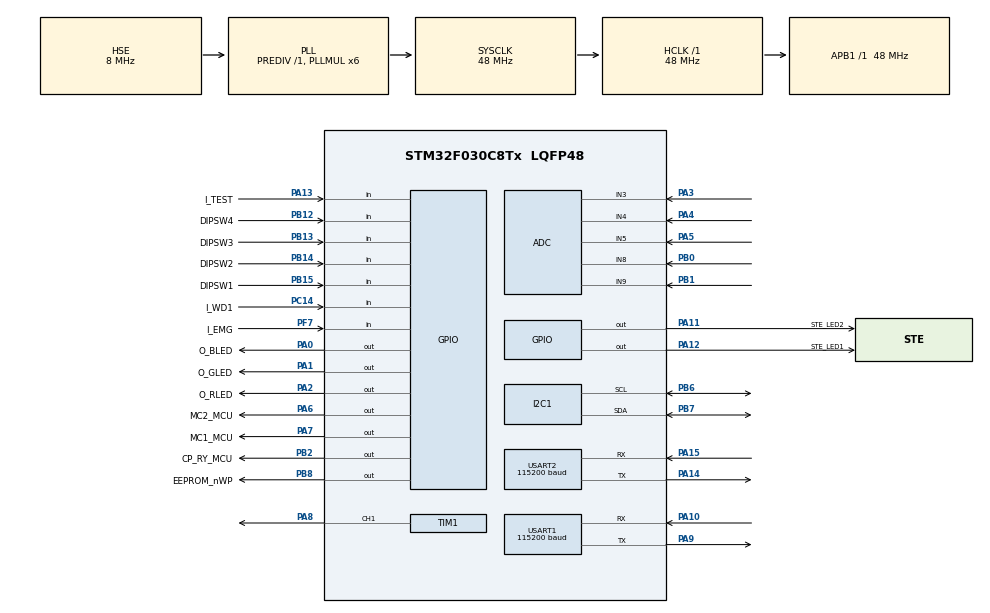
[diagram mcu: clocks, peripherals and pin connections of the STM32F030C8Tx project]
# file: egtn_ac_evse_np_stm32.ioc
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Mcu.Family=STM32F0
Dma.ADC.0.Mode=DMA_CIRCULAR
USART1.BaudRate=115200
PB14.GPIO_Label=DIPSW2
PA0.GPIO_Label=O_BLED
Dma.ADC.0.Priority=DMA_PRIORITY_LOW
PA6.GPIO_Label=MC2_MCU
PB13.GPIO_Label=DIPSW3
PB15.Signal=GPIO_Input
PB13.Signal=GPIO_Input
RCC.SYSCLKSource=RCC_SYSCLKSOURCE_PLLCLK
ProjectManager.StackSize=0x400
PA12.Signal=GPIO_Output
TIM1.Prescaler=1
PA4.Mode=IN4
PF7.Signal=GPIO_Input
Dma.ADC.0.PeriphInc=DMA_PINC_DISABLE
RCC.HCLKFreq_Value=48000000
TIM3.Period=2399
PB6.Signal=I2C1_SCL
PB6.Mode=I2C
RCC.AHBFreq_Value=48000000
Dma.ADC.0.Direction=DMA_PERIPH_TO_MEMORY
ADC.SamplingTime=ADC_SAMPLETIME_28CYCLES_5
PB2.Signal=GPIO_Output
USART2.VirtualMode-Asynchronous=VM_ASYNC
PA15.Mode=Asynchronous
RCC.PLLMUL=RCC_PLL_MUL6
PB12.GPIO_Label=DIPSW4
PF7.GPIO_Label=I_EMG
TIM1.Channel-PWM\ Generation1\ CH1=TIM_CHANNEL_1
PA14.Mode=Asynchronous
TIM3.Prescaler=1
PB7.Signal=I2C1_SDA
PA8.Signal=S_TIM1_CH1
PA0.Signal=GPIO_Output
Dma.ADC.0.MemInc=DMA_MINC_ENABLE
Mcu.Package=LQFP48
PB1.Signal=ADC_IN9
PA6.Signal=GPIO_Output
PA2.GPIO_Label=O_RLED
Dma.ADC.0.Instance=DMA1_Channel1
PA10.Signal=USART1_RX
PA15.Signal=USART2_RX
Dma.ADC.0.MemDataAlignment=DMA_MDATAALIGN_HALFWORD
RCC.APB1TimFreq_Value=48000000
PC14-OSC32_IN.GPIO_Label=I_WD1
TIM1.Period=23999
NVIC.USART1_IRQn=true\:0\:0\:false\:false\:true\:true\:true
PF1-OSC_OUT.Mode=HSE-External-Oscillator
Dma.Request0=ADC
PF1-OSC_OUT.Signal=RCC_OSC_OUT
PA3.Signal=ADC_IN3
PA5.Mode=IN5
RCC.PLLSourceVirtual=RCC_PLLSOURCE_HSE
TIM1.Pulse-Output\ Compare3\ No\ Output=22800
TIM3.Channel-Output\ Compare1\ No\ Output=TIM_CHANNEL_1
PA10.Mode=Asynchronous
TIM1.Channel-Output\ Compare2\ No\ Output=TIM_CHANNEL_2
PA11.GPIO_Label=STE_LED2
TIM1.Pulse-Output\ Compare4\ No\ Output=12000
PC14-OSC32_IN.Signal=GPIO_Input
ADC.ClockPrescaler=ADC_CLOCK_SYNC_PCLK_DIV4
NVIC.USART2_IRQn=true\:0\:0\:false\:false\:true\:true\:true
USART2.BaudRate=115200
PA12.GPIO_Label=STE_LED1
Dma.ADC.0.PeriphDataAlignment=DMA_PDATAALIGN_HALFWORD
USART1.VirtualMode-Asynchronous=VM_ASYNC
PA13.Signal=GPIO_Input
PA3.Mode=IN3
PB8.GPIO_Label=EEPROM_nWP
PA9.Mode=Asynchronous
SH.S_TIM1_CH1.0=TIM1_CH1,PWM Generation1 CH1
ProjectManager.TargetToolchain=STM32CubeIDE
PA9.Signal=USART1_TX
TIM1.Pulse-Output\ Compare2\ No\ Output=1200
PA1.Signal=GPIO_Output
PF0-OSC_IN.Mode=HSE-External-Oscillator
PB14.Signal=GPIO_Input
PA5.Signal=ADC_IN5
TIM1.Channel-Output\ Compare3\ No\ Output=TIM_CHANNEL_3
ADC.DMAContinuousRequests=ENABLE
PB0.Mode=IN8
board=custom
VP_TIM3_VS_no_output1.Mode=Output Compare1 No Output
NVIC.TIM3_IRQn=true\:0\:0\:false\:false\:true\:true\:true
VP_TIM1_VS_no_output4.Mode=Output Compare4 No Output
PB15.GPIO_Label=DIPSW1
VP_TIM1_VS_no_output3.Mode=Output Compare3 No Output
PA1.GPIO_Label=O_GLED
VP_TIM1_VS_no_output2.Mode=Output Compare2 No Output
Mcu.Name=STM32F030C8Tx
PA2.Signal=GPIO_Output
PA13.GPIO_Label=I_TEST
NVIC.TIM1_CC_IRQn=true\:0\:0\:false\:false\:true\:true\:true
ADC.Overrun=ADC_OVR_DATA_OVERWRITTEN
PA4.Signal=ADC_IN4
RCC.SYSCLKFreq_VALUE=48000000
PA7.GPIO_Label=MC1_MCU
PB7.Mode=I2C
PA11.Signal=GPIO_Output
PA14.Signal=USART2_TX
PB2.GPIO_Label=CP_RY_MCU
ProjectManager.HeapSize=0x200
PB1.Mode=IN9
TIM1.Channel-Output\ Compare4\ No\ Output=TIM_CHANNEL_4
PB8.Signal=GPIO_Output
NVIC.DMA1_Channel1_IRQn=true\:0\:0\:false\:false\:true\:false\:true
PF0-OSC_IN.Signal=RCC_OSC_IN
RCC.APB1Freq_Value=48000000
PB0.Signal=ADC_IN8
ADC.ContinuousConvMode=ENABLE
NVIC.TIM1_BRK_UP_TRG_COM_IRQn=true\:0\:0\:false\:false\:true\:true\:true
PB12.Signal=GPIO_Input
PA7.Signal=GPIO_Output

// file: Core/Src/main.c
/* USER CODE BEGIN Header */
/**
  ******************************************************************************
  * @file           : main.c
  * @brief          : Main program body
  ******************************************************************************
  * @attention
  *
  * <h2><center>&copy; Copyright (c) 2023 STMicroelectronics.
  * All rights reserved.</center></h2>
  *
  * This software component is licensed by ST under BSD 3-Clause license,
  * the "License"; You may not use this file except in compliance with the
  * License. You may obtain a copy of the License at:
  *                        opensource.org/licenses/BSD-3-Clause
  *
  ******************************************************************************
  */
/* USER CODE END Header */
#include "main.h"
#include "adc.h"
#include "dma.h"
#include "i2c.h"
#include "tim.h"
#include "usart.h"
#include "gpio.h"

/* USER CODE BEGIN Includes */
#include <_app_nonos_loop.h>
/* USER CODE END Includes */

void SystemClock_Config(void);

int main(void)
{

  /* MCU Configuration--------------------------------------------------------*/

  /* Reset of all peripherals, Initializes the Flash interface and the Systick. */
  HAL_Init();

  /* Configure the system clock */
  SystemClock_Config();

  /* Initialize all configured peripherals */
  MX_GPIO_Init();
  MX_DMA_Init();
  MX_ADC_Init();
  MX_I2C1_Init();
  MX_TIM1_Init();
  MX_TIM3_Init();
  MX_USART1_UART_Init();
  MX_USART2_UART_Init();

  /* Infinite loop */
  /* USER CODE BEGIN WHILE */
  while (1)
  {
	  acevsesystem();
    /* USER CODE END WHILE */

  }
}

void SystemClock_Config(void)
{
  RCC_OscInitTypeDef RCC_OscInitStruct = {0};
  RCC_ClkInitTypeDef RCC_ClkInitStruct = {0};
  RCC_PeriphCLKInitTypeDef PeriphClkInit = {0};

  /** Initializes the RCC Oscillators according to the specified parameters
  * in the RCC_OscInitTypeDef structure.
  */
  RCC_OscInitStruct.OscillatorType = RCC_OSCILLATORTYPE_HSI|RCC_OSCILLATORTYPE_HSE;
  RCC_OscInitStruct.HSEState = RCC_HSE_ON;
  RCC_OscInitStruct.HSIState = RCC_HSI_ON;
  RCC_OscInitStruct.HSICalibrationValue = RCC_HSICALIBRATION_DEFAULT;
  RCC_OscInitStruct.PLL.PLLState = RCC_PLL_ON;
  RCC_OscInitStruct.PLL.PLLSource = RCC_PLLSOURCE_HSE;
  RCC_OscInitStruct.PLL.PLLMUL = RCC_PLL_MUL6;
  RCC_OscInitStruct.PLL.PREDIV = RCC_PREDIV_DIV1;
  if (HAL_RCC_OscConfig(&RCC_OscInitStruct) != HAL_OK)
  {
    Error_Handler();
  }
  /** Initializes the CPU, AHB and APB buses clocks
  */
  RCC_ClkInitStruct.ClockType = RCC_CLOCKTYPE_HCLK|RCC_CLOCKTYPE_SYSCLK
                              |RCC_CLOCKTYPE_PCLK1;
  RCC_ClkInitStruct.SYSCLKSource = RCC_SYSCLKSOURCE_PLLCLK;
  RCC_ClkInitStruct.AHBCLKDivider = RCC_SYSCLK_DIV1;
  RCC_ClkInitStruct.APB1CLKDivider = RCC_HCLK_DIV1;

  if (HAL_RCC_ClockConfig(&RCC_ClkInitStruct, FLASH_LATENCY_1) != HAL_OK)
  {
    Error_Handler();
  }
  PeriphClkInit.PeriphClockSelection = RCC_PERIPHCLK_USART1|RCC_PERIPHCLK_I2C1;
  PeriphClkInit.Usart1ClockSelection = RCC_USART1CLKSOURCE_PCLK1;
  PeriphClkInit.I2c1ClockSelection = RCC_I2C1CLKSOURCE_HSI;
  if (HAL_RCCEx_PeriphCLKConfig(&PeriphClkInit) != HAL_OK)
  {
    Error_Handler();
  }
}

void Error_Handler(void)
{
  __disable_irq();
  while (1)
  {
  }
}

/************************ (C) COPYRIGHT STMicroelectronics *****END OF FILE****/
